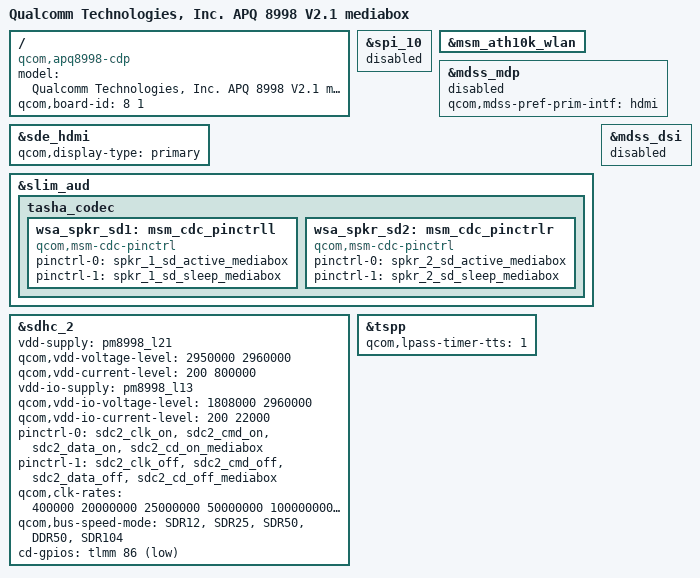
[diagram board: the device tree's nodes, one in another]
/* Copyright (c) 2016-2017, The Linux Foundation. All rights reserved.
 *
 * This program is free software; you can redistribute it and/or modify
 * it under the terms of the GNU General Public License version 2 and
 * only version 2 as published by the Free Software Foundation.
 *
 * This program is distributed in the hope that it will be useful,
 * but WITHOUT ANY WARRANTY; without even the implied warranty of
 * MERCHANTABILITY or FITNESS FOR A PARTICULAR PURPOSE.  See the
 * GNU General Public License for more details.
 */

/dts-v1/;

#include "apq8998-v2.1.dtsi"
#include "msm8998-cdp.dtsi"

/ {
	model = "Qualcomm Technologies, Inc. APQ 8998 V2.1 mediabox";
	compatible = "qcom,apq8998-cdp", "qcom,apq8998", "qcom,cdp";
	qcom,board-id = <8 1>;
};

&spi_10 {
	status = "disabled";
};

&msm_ath10k_wlan {
	status = "ok";
};

&mdss_mdp {
	status = "disabled";
	qcom,mdss-pref-prim-intf = "hdmi";
};

&sde_hdmi {
	qcom,display-type = "primary";
};

&slim_aud {
	tasha_codec {
		wsa_spkr_sd1: msm_cdc_pinctrll {
		      compatible = "qcom,msm-cdc-pinctrl";
		      pinctrl-names = "aud_active", "aud_sleep";
		      pinctrl-0 = <&spkr_1_sd_active_mediabox>;
		      pinctrl-1 = <&spkr_1_sd_sleep_mediabox>;
		};

		wsa_spkr_sd2: msm_cdc_pinctrlr {
		      compatible = "qcom,msm-cdc-pinctrl";
		      pinctrl-names = "aud_active", "aud_sleep";
		      pinctrl-0 = <&spkr_2_sd_active_mediabox>;
		      pinctrl-1 = <&spkr_2_sd_sleep_mediabox>;
		};
	};
};

&mdss_dsi {
	status = "disabled";
};

&sdhc_2 {
	vdd-supply = <&pm8998_l21>;
	qcom,vdd-voltage-level = <2950000 2960000>;
	qcom,vdd-current-level = <200 800000>;

	vdd-io-supply = <&pm8998_l13>;
	qcom,vdd-io-voltage-level = <1808000 2960000>;
	qcom,vdd-io-current-level = <200 22000>;

	pinctrl-names = "active", "sleep";
	pinctrl-0 = <&sdc2_clk_on  &sdc2_cmd_on &sdc2_data_on
			&sdc2_cd_on_mediabox>;
	pinctrl-1 = <&sdc2_clk_off &sdc2_cmd_off &sdc2_data_off
			&sdc2_cd_off_mediabox>;

	qcom,clk-rates = <400000 20000000 25000000
				50000000 100000000 200000000>;
	qcom,bus-speed-mode = "SDR12", "SDR25", "SDR50", "DDR50", "SDR104";

	cd-gpios = <&tlmm 86 0x1>;

	status = "ok";
};

&tspp {
	qcom,lpass-timer-tts = <1>;
};
